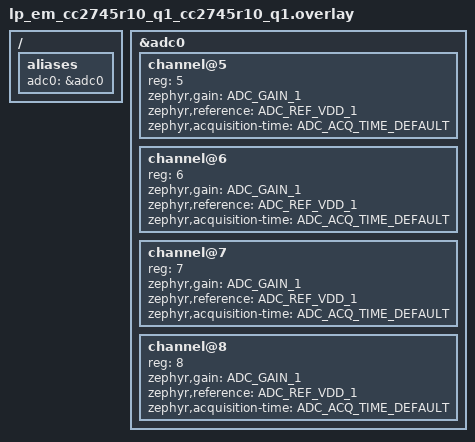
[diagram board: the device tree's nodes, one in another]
/*
 * Copyright (c) 2025 Texas Instruments Incorporated
 * Copyright (c) 2024 BayLibre, SAS
 *
 * SPDX-License-Identifier: Apache-2.0
 */

#include <zephyr/dt-bindings/adc/adc.h>

/ {
	aliases {
		adc0 = &adc0;
	};
};

&adc0 {
	status = "okay";

	#address-cells = <1>;
	#size-cells = <0>;

	channel@5 {
		reg = <5>;
		zephyr,gain = "ADC_GAIN_1";
		zephyr,reference = "ADC_REF_VDD_1";
		zephyr,acquisition-time = <ADC_ACQ_TIME_DEFAULT>;
		//zephyr,acquisition-time = <ADC_ACQ_TIME(ADC_ACQ_TIME_MICROSECONDS, 20)>;
	};

	channel@6 {
		reg = <6>;
		zephyr,gain = "ADC_GAIN_1";
		zephyr,reference = "ADC_REF_VDD_1";
		zephyr,acquisition-time = <ADC_ACQ_TIME_DEFAULT>;
		//zephyr,acquisition-time = <ADC_ACQ_TIME(ADC_ACQ_TIME_MICROSECONDS, 20)>;
	};

	channel@7 {
		reg = <7>;
		zephyr,gain = "ADC_GAIN_1";
		zephyr,reference = "ADC_REF_VDD_1";
		zephyr,acquisition-time = <ADC_ACQ_TIME_DEFAULT>;
		//zephyr,acquisition-time = <ADC_ACQ_TIME(ADC_ACQ_TIME_MICROSECONDS, 20)>;
	};

	channel@8 {
		reg = <8>;
		zephyr,gain = "ADC_GAIN_1";
		zephyr,reference = "ADC_REF_VDD_1";
		zephyr,acquisition-time = <ADC_ACQ_TIME_DEFAULT>;
		//zephyr,acquisition-time = <ADC_ACQ_TIME(ADC_ACQ_TIME_MICROSECONDS, 20)>;
	};
};
